# ADuCM362 register map
Vendor: Analog Devices Inc.; Series: ADuCM36x; File version: 0.1
CPU: CM3 r2p1, little endian, no MPU, no FPU, 3 interrupt priority bits
Registers are 16-bit, read-write, no defined reset value unless marked. A register's access mark holds for its fields unless they carry their own. Offsets are from the block's base; [hi:lo] are bit positions; {n}, {i} and the like mark numbered series.

## ADI_ADC1 — Analog to Digital Converter
Base 0x40030080
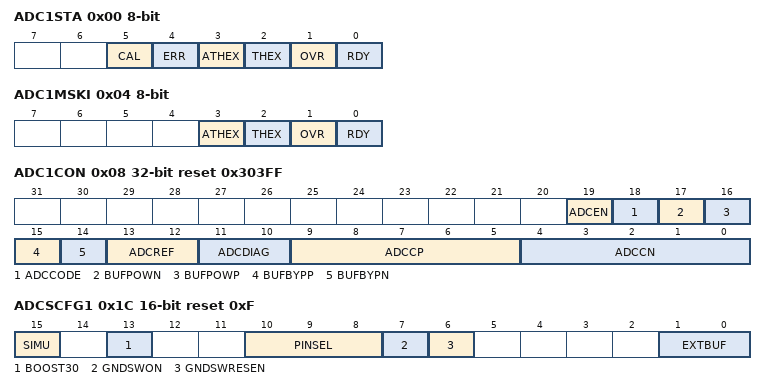
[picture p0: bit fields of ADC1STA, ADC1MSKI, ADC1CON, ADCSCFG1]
0x00 ADC1STA 8-bit ro — ADC Status register
  [all] fields
    0=DIS; 1=EN
  [5] CAL — ADC Calibration status register
  [4] ERR — ADC conversion error status bit.
  [3] ATHEX — ADC Accumulator Comparator Threshold status bit.
  [2] THEX — ADC comparator threshold.
  [1] OVR — ADC overrange bit.
  [0] RDY — valid conversion result
0x04 ADC1MSKI 8-bit — Interrupt control register
  [all] fields
    0=DIS; 1=EN
  [3] ATHEX — ADC Accumulator Comparator Threshold status bit mask
  [2] THEX — ADC comparator threshold mask
  [1] OVR — ADC overrange bit mask.
  [0] RDY — valid conversion result mask
0x08 ADC1CON 32-bit reset 0x303FF (reset mask 0x0) — Main control register
  [19] ADCEN — Enable Bit
    0=DIS; 1=EN
  [18] ADCCODE — ADC Output Coding bits
    0=INT; 1=UINT
  [17] BUFPOWN — Negative buffer power down
    0=DIS (Disable powerdown - Negative buffer is enabled); 1=EN (Enable powerdown - Negative buffer is disabled)
  [16] BUFPOWP — Positive buffer power down
    0=DIS (Disable powerdown - Positive buffer is enabled); 1=EN (Enable powerdown - Positive buffer is disabled)
  [15] BUFBYPP — Positive buffer bypass
    0=DIS; 1=EN
  [14] BUFBYPN — Negative buffer bypass
    0=DIS; 1=EN
  [13:12] ADCREF — Reference selection
    0=INTREF; 1=EXTREF; 2=EXTREF2; 3=AVDDREF
  [11:10] ADCDIAG — Diagnostic Current bits bits
    0=DIAG_OFF; 1=DIAG_POS; 2=DIAG_NEG; 3=DIAG_ALL
  [9:5] ADCCP — AIN+ bits
    {v}=AIN{v} (v=0..11); 12=DAC; 13=AVDD4; 14=IOVDD4; 15=AGND; 16=TEMP
  [4:0] ADCCN — AIN- bits
    {v}=AIN{v} (v=0..11); 12=DAC; 15=AGND; 17=TEMP
0x0C ADC1OF — Offset calibration register
  [15:0] VALUE range 0x00000000..0x0000FFFF — Offset
0x10 ADC1INTGN reset 0x5555 (reset mask 0x0) — Gain calibration register when using internal reference
  [15:0] VALUE range 0x00000000..0x0000FFFF — Gain with Int Ref
0x14 ADC1EXTGN reset 0x5555 (reset mask 0x0) — Gain calibration register when using external reference
  [15:0] VALUE range 0x00000000..0x0000FFFF — Gain with Ext Ref
0x18 ADC1VDDGN reset 0x5555 (reset mask 0x0) — Gain calibration register when using AVDD as the ADC reference
  [15:0] VALUE range 0x00000000..0x0000FFFF — Gain with Avdd Ref
0x1C ADCSCFG1 reset 0xF (reset mask 0x0) — Control register for the VBIAS voltage generator, ground switch and external reference buffer
  [15] SIMU — Enable both ADCs
    0=DIS; 1=EN
  [13] BOOST30 — Boost the Vbias current source ability by 30 times
    0=DIS; 1=EN
  [10:8] PINSEL — Enable vbias generator, send vbias to selected ain pin bits
    0=DIS (Disable VBIAS generator); 4=AIN7; 6=AIN11
  [7] GNDSWON — GND_SW
    0=DIS; 1=EN
  [6] GNDSWRESEN — 20k resistor in series with GND_SW
    0=DIS; 1=EN
  [1:0] EXTBUF — Control signals for ext_ref buffers bits
    0=OFF; 1=VREFPN; 2=VREFP_VREF2P
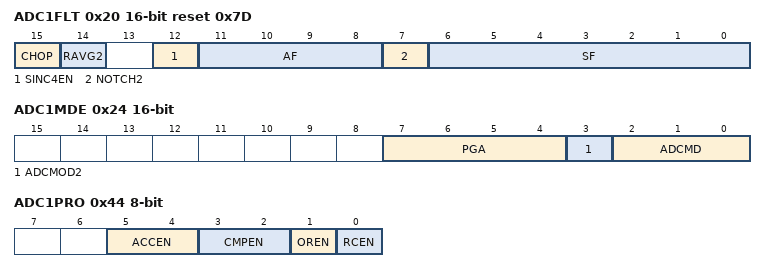
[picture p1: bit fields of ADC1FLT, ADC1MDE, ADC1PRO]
0x20 ADC1FLT reset 0x7D (reset mask 0x0) — Filter configuration register
  [15] CHOP — Enables System-Chopping bits
    0=OFF; 1=ON
  [14] RAVG2 — Enables a running Average-By-2 bits
    0=OFF; 1=ON
  [12] SINC4EN — Enable the Sinc4 filter instead of Sinc3 filter.
    0=DIS; 1=EN
  [11:8] AF range 0x00000000..0x0000000F — Averaging filter
  [7] NOTCH2 — Inserts a notch at FNOTCH2
    0=DIS; 1=EN
  [6:0] SF range 0x00000000..0x0000007F — SINC Filter value
0x24 ADC1MDE — mode control register
  [7:4] PGA — PGA Gain Select bit
    0=G1; 1=G2; 2=G4; 3=G8; 4=G16; 5=G32; 6=G64; 7=G128
  [3] ADCMOD2 — ADC modulator gain of 2 control bits
    0=MOD2OFF; 1=MOD2ON
  [2:0] ADCMD — ADC Mode bits
    0=OFF; 1=CONT; 2=SINGLE; 3=IDLE; 4=INTOCAL; 5=INTGCAL; 6=SYSOCAL; 7=SYSGCAL
0x28 ADC1RCR reset 0x1 (reset mask 0x0) — Number of ADC1 conversions before an ADC interrupt is generated.
  [15:0] VALUE range 0x00000000..0x0000FFFF
0x2C ADC1RCV ro — This 16-bit, read-only MMR holds the current number of ADC1 conversion results
  [15:0] VALUE range 0x00000000..0x0000FFFF
0x30 ADC1TH — Sets the threshold
  [15:0] VALUE range 0x00000000..0x0000FFFF
0x34 ADC1THC 8-bit reset 0x1 (reset mask 0x0) — Determines how many cumulative ADC1 conversion result readings above ADC1TH must occur
  [7:0] VALUE range 0x00000000..0x000000FF
0x38 ADC1THV 8-bit ro — 8-bit threshold exceeded counter register
  [7:0] VALUE range 0x00000000..0x000000FF
0x3C ADC1ACC 32-bit ro — 32-bit accumulator register
  [31:0] VALUE range 0x00000000..0xFFFFFFFF
0x40 ADC1ATH 32-bit — Holds the threshold value for the accumulator comparator
  [31:0] VALUE range 0x00000000..0xFFFFFFFF
0x44 ADC1PRO 8-bit — Configuration register for Post processing of ADC1 results
  [5:4] ACCEN — ADC Accumulator Enable bits
    0=Off; 1=En; 2=EnNDec; 3=EnAccCnt
  [3:2] CMPEN — ADC Comparator Enable bits
    0=Off; 1=En; 2=EnCnt; 3=EnCntDec
  [1] OREN — ADC OverRange Enable
    0=DIS; 1=EN
  [0] RCEN — ADC Result Counter Enable
    0=DIS; 1=EN
0x48 ADC1DAT 32-bit ro — conversion result register
  [31:0] VALUE range 0x00000000..0xFFFFFFFF
